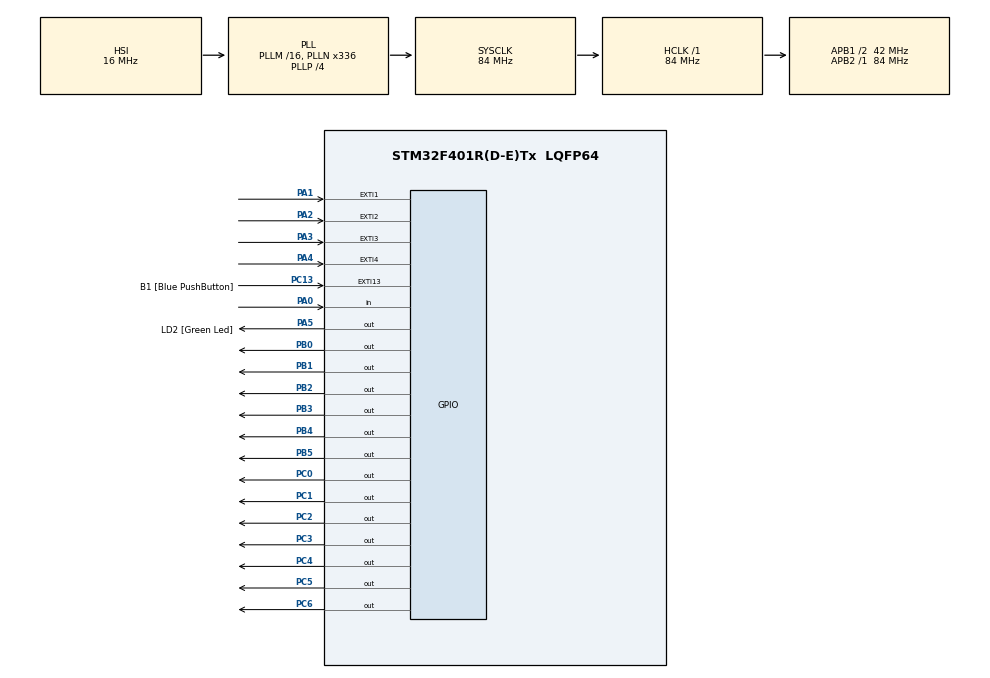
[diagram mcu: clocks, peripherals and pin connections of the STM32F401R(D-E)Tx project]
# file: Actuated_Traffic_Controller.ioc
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Mcu.Family=STM32F4
Mcu.Name=STM32F401R(D-E)Tx
Mcu.Package=LQFP64
NVIC.EXTI1_IRQn=true\:0\:0\:false\:false\:true\:true\:true\:true
NVIC.EXTI2_IRQn=true\:0\:0\:false\:false\:true\:true\:true\:true
NVIC.EXTI3_IRQn=true\:0\:0\:false\:false\:true\:true\:true\:true
NVIC.EXTI4_IRQn=true\:0\:0\:false\:false\:true\:true\:true\:true
NVIC.PriorityGroup=NVIC_PRIORITYGROUP_4
PA0-WKUP.Signal=GPIO_Input
PA1.GPIO_ModeDefaultEXTI=GPIO_MODE_IT_FALLING
PA1.GPIO_PuPd=GPIO_PULLDOWN
PA1.Signal=GPXTI1
PA13.GPIO_Label=TMS
PA13.Signal=SYS_JTMS-SWDIO
PA14.GPIO_Label=TCK
PA14.Signal=SYS_JTCK-SWCLK
PA2.GPIO_ModeDefaultEXTI=GPIO_MODE_IT_FALLING
PA2.GPIO_PuPd=GPIO_PULLDOWN
PA2.Signal=GPXTI2
PA3.GPIO_ModeDefaultEXTI=GPIO_MODE_IT_FALLING
PA3.GPIO_PuPd=GPIO_PULLDOWN
PA3.Signal=GPXTI3
PA4.GPIO_ModeDefaultEXTI=GPIO_MODE_IT_FALLING
PA4.GPIO_PuPd=GPIO_PULLDOWN
PA4.Signal=GPXTI4
PA5.GPIO_Label=LD2 [Green Led]
PA5.GPIO_Mode=GPIO_MODE_OUTPUT_PP
PA5.GPIO_PuPd=GPIO_NOPULL
PA5.GPIO_Speed=GPIO_SPEED_FREQ_LOW
PA5.Signal=GPIO_Output
PB0.Signal=GPIO_Output
PB1.Signal=GPIO_Output
PB2.Signal=GPIO_Output
PB3.Signal=GPIO_Output
PB4.Signal=GPIO_Output
PB5.Signal=GPIO_Output
PC0.Signal=GPIO_Output
PC1.Signal=GPIO_Output
PC13-ANTI_TAMP.GPIO_Label=B1 [Blue PushButton]
PC13-ANTI_TAMP.GPIO_ModeDefaultEXTI=GPIO_MODE_IT_FALLING
PC13-ANTI_TAMP.GPIO_PuPd=GPIO_NOPULL
PC13-ANTI_TAMP.Signal=GPXTI13
PC14-OSC32_IN.Mode=LSE-External-Oscillator
PC14-OSC32_IN.Signal=RCC_OSC32_IN
PC15-OSC32_OUT.Mode=LSE-External-Oscillator
PC15-OSC32_OUT.Signal=RCC_OSC32_OUT
PC2.Signal=GPIO_Output
PC3.Signal=GPIO_Output
PC4.Signal=GPIO_Output
PC5.Signal=GPIO_Output
PC6.Signal=GPIO_Output
PH0\ -\ OSC_IN.Mode=HSE-External-Clock-Source
PH0\ -\ OSC_IN.Signal=RCC_OSC_IN
PH1\ -\ OSC_OUT.Mode=HSE-External-Clock-Source
PH1\ -\ OSC_OUT.Signal=RCC_OSC_OUT
ProjectManager.HeapSize=0x200
ProjectManager.StackSize=0x400
ProjectManager.TargetToolchain=STM32CubeIDE
RCC.48MHZClocksFreq_Value=48000000
RCC.AHBFreq_Value=84000000
RCC.APB1CLKDivider=RCC_HCLK_DIV2
RCC.APB1Freq_Value=42000000
RCC.APB1TimFreq_Value=84000000
RCC.APB2Freq_Value=84000000
RCC.APB2TimFreq_Value=84000000
RCC.CortexFreq_Value=84000000
RCC.HCLKFreq_Value=84000000
RCC.HSE_VALUE=8000000
RCC.HSI_VALUE=16000000
RCC.PLLN=336
RCC.PLLP=RCC_PLLP_DIV4
RCC.PLLQ=7
RCC.SYSCLKFreq_VALUE=84000000
RCC.SYSCLKSource=RCC_SYSCLKSOURCE_PLLCLK
RCC.VCOOutputFreq_Value=336000000
board=NUCLEO-F401RE

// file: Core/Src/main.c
/* USER CODE BEGIN Header */
/**
 ******************************************************************************
 * @file           : main.c
 * @brief          : Main program body
 ******************************************************************************
 * @attention
 *
 * Copyright (c) 2025 STMicroelectronics.
 * All rights reserved.
 *
 * This software is licensed under terms that can be found in the LICENSE file
 * in the root directory of this software component.
 * If no LICENSE file comes with this software, it is provided AS-IS.
 *
 ******************************************************************************
 */
/* USER CODE END Header */
#include "main.h"

void SystemClock_Config(void);
static void MX_GPIO_Init(void);

#define MAX_SIZE 10

int queue[MAX_SIZE] = { 0 };
int front = -1, rear = -1;
int pin = 0;

// Function to check if the queue is full
int isFull() {
	// If the next position is the front, the queue is full
	return (rear + 1) % MAX_SIZE == front;
}

// Function to check if the queue is empty
int isEmpty() {
	// If the front hasn't been set, the queue is empty

	if (front == -1) {
		return 1;
	} else {
		return 0;
	}
}

// Function to enqueue (insert) an element
void enqueue(int data) {
	// If the queue is full, print an error message and
	// return
	if (isFull()) {
		//printf("Queue overflow\n");
		return;
	}
	// If the queue is empty, set the front to the first
	// position
	if (front == -1) {
		front = 0;
	}

	int insert = 1;
	// Add the data to the queue and move the rear pointer
	int i = front;
	do {
		if (queue[i] == data) {
			insert = 0;
			break;
		}
		i = (i + 1) % MAX_SIZE;
	} while (i != (rear + 1) % MAX_SIZE);

	if (insert == 1) {
		rear = (rear + 1) % MAX_SIZE;
		queue[rear] = data;
	}

	//printf("Element %d inserted\n", data);
}

// Function to dequeue (remove) an element
int dequeue() {
	// If the queue is empty, print an error message and
	// return -1
	if (isEmpty()) {
		//printf("Queue underflow\n");
		return -1;
	}
	// Get the data from the front of the queue
	int data = queue[front];
	queue[front] = 0;
	// If the front and rear pointers are at the same
	// position, reset them
	if (front == rear) {
		front = -1;
		rear = -1;
	} else {
		// Otherwise, move the front pointer to the next
		// position
		front = (front + 1) % MAX_SIZE;
	}
	// Return the dequeued data
	return data;
}

int sec = 1000;

int green_timer = 0;
int default_green = 5;
int min_green = 1;
int max_green = 12;

volatile int green_duration = 5;

void MAJOR_TURNS(void) {
	GPIOB->ODR = 0b00001001;  // MAJOR LEFT RED AND FORWARD RED
	//HAL_Delay(2 * sec);

	GPIOC->ODR = 0b00001001;  // LEFT RED AND FORWARD RED
	HAL_Delay(2 * sec);

	GPIOC->ODR = 0b00100001;  // LEFT GREEN AND FORWARD RED
	HAL_Delay(5 * sec);

	GPIOC->ODR = 0b00010001;  // LEFT YELLOW AND FORWARD RED
	HAL_Delay(1 * sec);

	GPIOC->ODR = 0b00001001;  // LEFT RED AND FORWARD RED
	HAL_Delay(2 * sec);

	GPIOC->ODR = 0b00001100;  // LEFT RED AND FORWARD GREEN
	HAL_Delay(5 * sec);

	GPIOC->ODR = 0b00001010;  // LEFT RED AND FORWARD YELLOW
	HAL_Delay(1 * sec);

	GPIOC->ODR = 0b00001001;  // LEFT RED AND FORWARD RED

}

void MINOR_TURNS(void) {
	GPIOC->ODR = 0b00001001;  // MAJOR LEFT RED AND FORWARD RED
	//HAL_Delay(2 * sec);

	GPIOB->ODR = 0b00001001;  // LEFT RED AND FORWARD RED
	HAL_Delay(2 * sec);

	GPIOB->ODR = 0b00100001;  // LEFT GREEN AND FORWARD RED
	HAL_Delay(5 * sec);

	GPIOB->ODR = 0b00010001;  // LEFT YELLOW AND FORWARD RED
	HAL_Delay(1 * sec);

	GPIOB->ODR = 0b00001001;  // LEFT RED AND FORWARD RED
	HAL_Delay(2 * sec);

	GPIOB->ODR = 0b00001100;  // LEFT RED AND FORWARD GREEN
	HAL_Delay(5 * sec);

	GPIOB->ODR = 0b00001010;  // LEFT RED AND FORWARD YELLOW
	HAL_Delay(1 * sec);

	GPIOB->ODR = 0b00001001;  // LEFT RED AND FORWARD RED
	HAL_Delay(1 * sec);
}

void MAJOR_LEFT_TURN(void) {
	green_duration = default_green;
	for (int i = 0; i < green_duration; i++) {
		GPIOC->ODR = 0b00100001;  // Major left green, forward red
		HAL_Delay(sec);
	}

	//HAL_Delay(5 * sec);
	GPIOC->ODR = 0b00010001;  // Major left yellow
	HAL_Delay(1 * sec);

	GPIOC->ODR = 0b00001001;  // LEFT RED AND FORWARD RED
	HAL_Delay(1 * sec);
}

void MAJOR_FORWARD(void) {
	green_duration = default_green;
	// Major forward green
	for (int i = 0; i < green_duration; i++) {
		GPIOC->ODR = 0b00001100;
		HAL_Delay(sec);
	}

	//HAL_Delay(5 * sec);
	GPIOC->ODR = 0b00001010;  // Major forward yellow
	HAL_Delay(1 * sec);

	GPIOC->ODR = 0b00001001;  // LEFT RED AND FORWARD RED
	HAL_Delay(1 * sec);
}

void MINOR_LEFT_TURN(void) {
	green_duration = default_green;
	// Minor left green, forward red

	for (int i = 0; i < green_duration; i++) {
		GPIOB->ODR = 0b00100001;
		HAL_Delay(sec);
	}

	//HAL_Delay(5 * sec);
	GPIOB->ODR = 0b00010001;  // Minor left yellow
	HAL_Delay(1 * sec);

	GPIOB->ODR = 0b00001001;  // LEFT RED AND FORWARD RED
	HAL_Delay(1 * sec);

}

void MINOR_FORWARD(void) {
	green_duration = default_green;
	// Minor forward green

	for (int i = 0; i < green_duration; i++) {
		GPIOB->ODR = 0b00001100;
		HAL_Delay(sec);
	}

	//HAL_Delay(5 * sec);
	GPIOB->ODR = 0b00001010;  // Minor forward yellow
	HAL_Delay(1 * sec);

	GPIOB->ODR = 0b00001001;  // LEFT RED AND FORWARD RED
	HAL_Delay(1 * sec);

}

int main(void) {

	/* MCU Configuration--------------------------------------------------------*/

	/* Reset of all peripherals, Initializes the Flash interface and the Systick. */
	HAL_Init();

	/* Configure the system clock */
	SystemClock_Config();

	/* Initialize all configured peripherals */
	MX_GPIO_Init();

	/* Infinite loop */
	/* USER CODE BEGIN WHILE */
	while (1) {

		if (front >= MAX_SIZE || rear >= MAX_SIZE) {
			// Reset the queue as it's been corrupted
			front = -1;
			rear = -1;
		}

		int current_value = queue[front];

		/* USER CODE END WHILE */
		if (HAL_GPIO_ReadPin(GPIOA, GPIO_PIN_0) == GPIO_PIN_SET) {
			MAJOR_TURNS();
			MINOR_TURNS();
		} else {
			//!isEmpty()
			if (!isEmpty()) {

				switch (current_value) {
				case 1:
					MAJOR_FORWARD();
					//dequeue();
					//pin = 0;
					break;

				case 2:
					MAJOR_LEFT_TURN();
					//dequeue();
					//pin = 0;
					break;

				case 3:

					MINOR_FORWARD();
					//dequeue();
					//pin = 0;
					break;

				case 4:
					MINOR_LEFT_TURN();
					//dequeue();
					//pin = 0;
					break;

				default:
					GPIOB->ODR = 0b00001001;
					GPIOC->ODR = 0b00001001;
					break;
				}

				dequeue();
				HAL_Delay(500);

			} else {
				GPIOB->ODR = 0b00001001;
				GPIOC->ODR = 0b00001001;
			}

		}

		/* USER CODE END 3 */
	}

}

void HAL_GPIO_EXTI_Callback(uint16_t GPIO_Pin) {

	switch (GPIO_Pin) {
	case GPIO_PIN_1:
		if (!isEmpty() && queue[front] == 1 && green_duration < max_green) {
			green_duration += min_green;
		}
		enqueue(1);
		break;

	case GPIO_PIN_5:
		if (!isEmpty() && queue[front] == 2 && green_duration < max_green) {
			green_duration += min_green;
		}
		enqueue(2);
		break;

	case GPIO_PIN_6:
		if (!isEmpty() && queue[front] == 3 && green_duration < max_green) {
			green_duration += min_green;
		}
		enqueue(3);
		break;

	case GPIO_PIN_4:

		if (!isEmpty() && queue[front] == 4 && green_duration < max_green) {
			green_duration += min_green;
		}
		enqueue(4);
		break;
	}

}

void SystemClock_Config(void) {
	RCC_OscInitTypeDef RCC_OscInitStruct = { 0 };
	RCC_ClkInitTypeDef RCC_ClkInitStruct = { 0 };

	/** Configure the main internal regulator output voltage
	 */
	__HAL_RCC_PWR_CLK_ENABLE();
	__HAL_PWR_VOLTAGESCALING_CONFIG(PWR_REGULATOR_VOLTAGE_SCALE2);

	/** Initializes the RCC Oscillators according to the specified parameters
	 * in the RCC_OscInitTypeDef structure.
	 */
	RCC_OscInitStruct.OscillatorType = RCC_OSCILLATORTYPE_HSI;
	RCC_OscInitStruct.HSIState = RCC_HSI_ON;
	RCC_OscInitStruct.HSICalibrationValue = RCC_HSICALIBRATION_DEFAULT;
	RCC_OscInitStruct.PLL.PLLState = RCC_PLL_ON;
	RCC_OscInitStruct.PLL.PLLSource = RCC_PLLSOURCE_HSI;
	RCC_OscInitStruct.PLL.PLLM = 16;
	RCC_OscInitStruct.PLL.PLLN = 336;
	RCC_OscInitStruct.PLL.PLLP = RCC_PLLP_DIV4;
	RCC_OscInitStruct.PLL.PLLQ = 7;
	if (HAL_RCC_OscConfig(&RCC_OscInitStruct) != HAL_OK) {
		Error_Handler();
	}

	/** Initializes the CPU, AHB and APB buses clocks
	 */
	RCC_ClkInitStruct.ClockType = RCC_CLOCKTYPE_HCLK | RCC_CLOCKTYPE_SYSCLK
			| RCC_CLOCKTYPE_PCLK1 | RCC_CLOCKTYPE_PCLK2;
	RCC_ClkInitStruct.SYSCLKSource = RCC_SYSCLKSOURCE_PLLCLK;
	RCC_ClkInitStruct.AHBCLKDivider = RCC_SYSCLK_DIV1;
	RCC_ClkInitStruct.APB1CLKDivider = RCC_HCLK_DIV2;
	RCC_ClkInitStruct.APB2CLKDivider = RCC_HCLK_DIV1;

	if (HAL_RCC_ClockConfig(&RCC_ClkInitStruct, FLASH_LATENCY_2) != HAL_OK) {
		Error_Handler();
	}
}

static void MX_GPIO_Init(void) {
	GPIO_InitTypeDef GPIO_InitStruct = { 0 };

	/* GPIO Ports Clock Enable */
	__HAL_RCC_GPIOC_CLK_ENABLE();
	__HAL_RCC_GPIOH_CLK_ENABLE();
	__HAL_RCC_GPIOA_CLK_ENABLE();
	__HAL_RCC_GPIOB_CLK_ENABLE();

	/*Configure GPIO pin Output Level */
	HAL_GPIO_WritePin(GPIOC,
			GPIO_PIN_0 | GPIO_PIN_1 | GPIO_PIN_2 | GPIO_PIN_3 | GPIO_PIN_4
					| GPIO_PIN_5 | GPIO_PIN_6, GPIO_PIN_RESET);

	/*Configure GPIO pin Output Level */
	HAL_GPIO_WritePin(LD2_GPIO_Port, LD2_Pin, GPIO_PIN_RESET);

	/*Configure GPIO pin Output Level */
	HAL_GPIO_WritePin(GPIOB,
	GPIO_PIN_0 | GPIO_PIN_1 | GPIO_PIN_2 | GPIO_PIN_3 | GPIO_PIN_4 | GPIO_PIN_5,
			GPIO_PIN_RESET);

	/*Configure GPIO pin : B1_Pin */
	GPIO_InitStruct.Pin = B1_Pin;
	GPIO_InitStruct.Mode = GPIO_MODE_IT_FALLING;
	GPIO_InitStruct.Pull = GPIO_NOPULL;
	HAL_GPIO_Init(B1_GPIO_Port, &GPIO_InitStruct);

	/*Configure GPIO pins : PC0 PC1 PC2 PC3
	 PC4 PC5 PC6 */
	GPIO_InitStruct.Pin = GPIO_PIN_0 | GPIO_PIN_1 | GPIO_PIN_2 | GPIO_PIN_3
			| GPIO_PIN_4 | GPIO_PIN_5 | GPIO_PIN_6;
	GPIO_InitStruct.Mode = GPIO_MODE_OUTPUT_PP;
	GPIO_InitStruct.Pull = GPIO_NOPULL;
	GPIO_InitStruct.Speed = GPIO_SPEED_FREQ_LOW;
	HAL_GPIO_Init(GPIOC, &GPIO_InitStruct);

	/*Configure GPIO pin : PA0 */
	GPIO_InitStruct.Pin = GPIO_PIN_0;
	GPIO_InitStruct.Mode = GPIO_MODE_INPUT;
	GPIO_InitStruct.Pull = GPIO_NOPULL;
	HAL_GPIO_Init(GPIOA, &GPIO_InitStruct);

	/*Configure GPIO pins : PA1 PA2 PA3 PA4 */
	GPIO_InitStruct.Pin = GPIO_PIN_1 | GPIO_PIN_4;
	GPIO_InitStruct.Mode = GPIO_MODE_IT_FALLING;
	GPIO_InitStruct.Pull = GPIO_PULLDOWN;
	HAL_GPIO_Init(GPIOA, &GPIO_InitStruct);

	/*Configure GPIO pin : LD2_Pin */
	GPIO_InitStruct.Pin = LD2_Pin;
	GPIO_InitStruct.Mode = GPIO_MODE_OUTPUT_PP;
	GPIO_InitStruct.Pull = GPIO_NOPULL;
	GPIO_InitStruct.Speed = GPIO_SPEED_FREQ_LOW;
	HAL_GPIO_Init(LD2_GPIO_Port, &GPIO_InitStruct);

	/*Configure GPIO pins : PB0 PB1 PB2 PB3
	 PB4 PB5 */
	GPIO_InitStruct.Pin = GPIO_PIN_0 | GPIO_PIN_1 | GPIO_PIN_2 | GPIO_PIN_3
			| GPIO_PIN_4 | GPIO_PIN_5;
	GPIO_InitStruct.Mode = GPIO_MODE_OUTPUT_PP;
	GPIO_InitStruct.Pull = GPIO_NOPULL;
	GPIO_InitStruct.Speed = GPIO_SPEED_FREQ_LOW;
	HAL_GPIO_Init(GPIOB, &GPIO_InitStruct);

	/* Configure replacement pins for PA2 and PA3 */
	GPIO_InitTypeDef GPIO_InitStruct_Replacement = { 0 };
	GPIO_InitStruct_Replacement.Pin = GPIO_PIN_5 | GPIO_PIN_6;  // New pins
	GPIO_InitStruct_Replacement.Mode = GPIO_MODE_IT_FALLING;
	GPIO_InitStruct_Replacement.Pull = GPIO_PULLDOWN;
	HAL_GPIO_Init(GPIOA, &GPIO_InitStruct_Replacement);

	/* EXTI interrupt init*/
	HAL_NVIC_SetPriority(EXTI1_IRQn, 2, 0);
	HAL_NVIC_EnableIRQ(EXTI1_IRQn);

	HAL_NVIC_SetPriority(EXTI4_IRQn, 5, 0);
	HAL_NVIC_EnableIRQ(EXTI4_IRQn);

	HAL_NVIC_SetPriority(EXTI9_5_IRQn, 2, 0);  // For pins 5-9
	HAL_NVIC_EnableIRQ(EXTI9_5_IRQn);

}

void EXTI9_5_IRQHandler(void) {
	HAL_GPIO_EXTI_IRQHandler(GPIO_PIN_5);
	HAL_GPIO_EXTI_IRQHandler(GPIO_PIN_6);
}

void Error_Handler(void) {
	__disable_irq();
	while (1) {
	}
}
